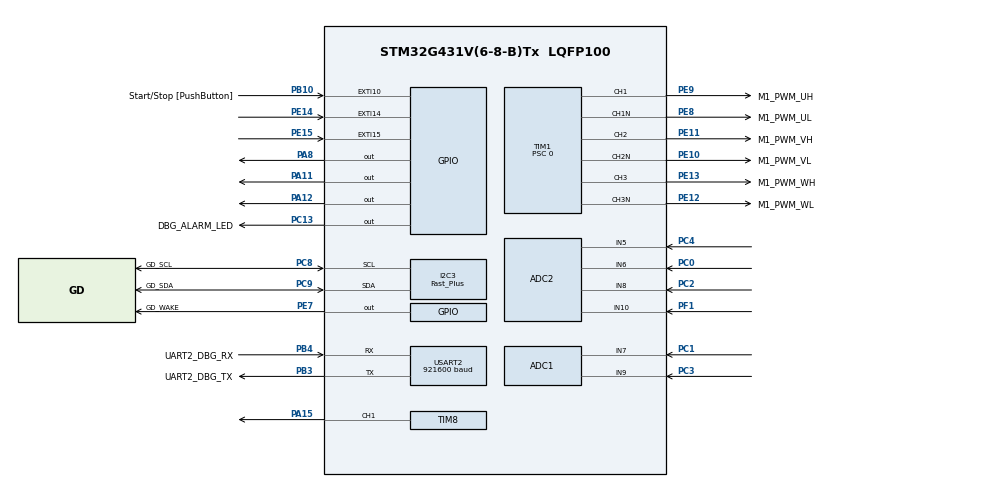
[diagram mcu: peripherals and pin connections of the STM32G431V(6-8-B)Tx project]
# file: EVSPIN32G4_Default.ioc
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ADC1.Channel-3\#ChannelRegularConversion=ADC_CHANNEL_7
ADC1.Channel-4\#ChannelRegularConversion=ADC_CHANNEL_9
ADC1.Channel-5\#ChannelRegularConversion=ADC_CHANNEL_9
ADC1.Channel-6\#ChannelRegularConversion=ADC_CHANNEL_7
ADC1.Channel-7\#ChannelRegularConversion=ADC_CHANNEL_7
ADC1.Channel-8\#ChannelRegularConversion=ADC_CHANNEL_7
ADC1.ClockPrescaler=ADC_CLOCK_ASYNC_DIV1
ADC1.DMAContinuousRequests=ENABLE
ADC1.DiscontinuousConvMode=ENABLE
ADC1.ExternalTrigConv=ADC_EXTERNALTRIG_T1_TRGO2
ADC1.ExternalTrigConvEdge=ADC_EXTERNALTRIGCONVEDGE_RISINGFALLING
ADC1.NbrOfConversion=6
ADC1.NbrOfConversionFlag=1
ADC1.OffsetNumber-3\#ChannelRegularConversion=ADC_OFFSET_NONE
ADC1.OffsetNumber-4\#ChannelRegularConversion=ADC_OFFSET_NONE
ADC1.OffsetNumber-5\#ChannelRegularConversion=ADC_OFFSET_NONE
ADC1.OffsetNumber-6\#ChannelRegularConversion=ADC_OFFSET_NONE
ADC1.OffsetNumber-7\#ChannelRegularConversion=ADC_OFFSET_NONE
ADC1.OffsetNumber-8\#ChannelRegularConversion=ADC_OFFSET_NONE
ADC1.Rank-3\#ChannelRegularConversion=1
ADC1.Rank-4\#ChannelRegularConversion=2
ADC1.Rank-5\#ChannelRegularConversion=3
ADC1.Rank-6\#ChannelRegularConversion=4
ADC1.Rank-7\#ChannelRegularConversion=5
ADC1.Rank-8\#ChannelRegularConversion=6
ADC1.SamplingTime-3\#ChannelRegularConversion=ADC_SAMPLETIME_6CYCLES_5
ADC1.SamplingTime-4\#ChannelRegularConversion=ADC_SAMPLETIME_6CYCLES_5
ADC1.SamplingTime-5\#ChannelRegularConversion=ADC_SAMPLETIME_6CYCLES_5
ADC1.SamplingTime-6\#ChannelRegularConversion=ADC_SAMPLETIME_6CYCLES_5
ADC1.SamplingTime-7\#ChannelRegularConversion=ADC_SAMPLETIME_6CYCLES_5
ADC1.SamplingTime-8\#ChannelRegularConversion=ADC_SAMPLETIME_6CYCLES_5
ADC1.master=1
ADC2.Channel-0\#ChannelRegularConversion=ADC_CHANNEL_5
ADC2.Channel-1\#ChannelRegularConversion=ADC_CHANNEL_8
ADC2.Channel-2\#ChannelRegularConversion=ADC_CHANNEL_10
ADC2.ClockPrescaler=ADC_CLOCK_ASYNC_DIV1
ADC2.DMAContinuousRequests=ENABLE
ADC2.DiscontinuousConvMode=ENABLE
ADC2.EOCSelection=ADC_EOC_SINGLE_CONV
ADC2.EnableInjectedConversion=ENABLE
ADC2.ExternalTrigInjecConv=ADC_EXTERNALTRIGINJEC_T8_TRGO2
ADC2.ExternalTrigInjecConvEdge=ADC_EXTERNALTRIGINJECCONV_EDGE_RISING
ADC2.InjNumberOfConversion=1
ADC2.InjectedChannel-3\#ChannelInjectedConversion=ADC_CHANNEL_6
ADC2.InjectedOffsetNumber-3\#ChannelInjectedConversion=ADC_OFFSET_NONE
ADC2.InjectedRank-3\#ChannelInjectedConversion=1
ADC2.InjectedSamplingTime-3\#ChannelInjectedConversion=ADC_SAMPLETIME_6CYCLES_5
ADC2.NbrOfConversion=3
ADC2.NbrOfConversionFlag=1
ADC2.NbrOfDiscConversion=3
ADC2.OffsetNumber-0\#ChannelRegularConversion=ADC_OFFSET_NONE
ADC2.OffsetNumber-1\#ChannelRegularConversion=ADC_OFFSET_NONE
ADC2.OffsetNumber-2\#ChannelRegularConversion=ADC_OFFSET_NONE
ADC2.Rank-0\#ChannelRegularConversion=1
ADC2.Rank-1\#ChannelRegularConversion=2
ADC2.Rank-2\#ChannelRegularConversion=3
ADC2.Rank1_Channel=ADC_CHANNEL_6
ADC2.SamplingTime-0\#ChannelRegularConversion=ADC_SAMPLETIME_6CYCLES_5
ADC2.SamplingTime-1\#ChannelRegularConversion=ADC_SAMPLETIME_6CYCLES_5
ADC2.SamplingTime-2\#ChannelRegularConversion=ADC_SAMPLETIME_6CYCLES_5
ADC2.injectedQueueMode=DISABLE
Dma.ADC1.0.Direction=DMA_PERIPH_TO_MEMORY
Dma.ADC1.0.EventEnable=DISABLE
Dma.ADC1.0.Instance=DMA1_Channel1
Dma.ADC1.0.MemDataAlignment=DMA_MDATAALIGN_HALFWORD
Dma.ADC1.0.MemInc=DMA_MINC_ENABLE
Dma.ADC1.0.Mode=DMA_CIRCULAR
Dma.ADC1.0.PeriphDataAlignment=DMA_PDATAALIGN_HALFWORD
Dma.ADC1.0.PeriphInc=DMA_PINC_DISABLE
Dma.ADC1.0.Polarity=HAL_DMAMUX_REQ_GEN_RISING
Dma.ADC1.0.Priority=DMA_PRIORITY_VERY_HIGH
Dma.ADC1.0.RequestNumber=1
Dma.ADC1.0.SignalID=NONE
Dma.ADC1.0.SyncEnable=DISABLE
Dma.ADC1.0.SyncPolarity=HAL_DMAMUX_SYNC_NO_EVENT
Dma.ADC1.0.SyncRequestNumber=1
Dma.ADC1.0.SyncSignalID=NONE
Dma.ADC2.2.Direction=DMA_PERIPH_TO_MEMORY
Dma.ADC2.2.EventEnable=DISABLE
Dma.ADC2.2.Instance=DMA1_Channel2
Dma.ADC2.2.MemDataAlignment=DMA_MDATAALIGN_HALFWORD
Dma.ADC2.2.MemInc=DMA_MINC_ENABLE
Dma.ADC2.2.Mode=DMA_CIRCULAR
Dma.ADC2.2.PeriphDataAlignment=DMA_PDATAALIGN_HALFWORD
Dma.ADC2.2.PeriphInc=DMA_PINC_DISABLE
Dma.ADC2.2.Polarity=HAL_DMAMUX_REQ_GEN_RISING
Dma.ADC2.2.Priority=DMA_PRIORITY_MEDIUM
Dma.ADC2.2.RequestNumber=1
Dma.ADC2.2.SignalID=NONE
Dma.ADC2.2.SyncEnable=DISABLE
Dma.ADC2.2.SyncPolarity=HAL_DMAMUX_SYNC_NO_EVENT
Dma.ADC2.2.SyncRequestNumber=1
Dma.ADC2.2.SyncSignalID=NONE
Dma.Request0=ADC1
Dma.Request1=TIM1_CH4
Dma.Request2=ADC2
Dma.TIM1_CH4.1.Direction=DMA_MEMORY_TO_PERIPH
Dma.TIM1_CH4.1.EventEnable=DISABLE
Dma.TIM1_CH4.1.Instance=DMA1_Channel4
Dma.TIM1_CH4.1.MemDataAlignment=DMA_MDATAALIGN_HALFWORD
Dma.TIM1_CH4.1.MemInc=DMA_MINC_ENABLE
Dma.TIM1_CH4.1.Mode=DMA_CIRCULAR
Dma.TIM1_CH4.1.PeriphDataAlignment=DMA_PDATAALIGN_HALFWORD
Dma.TIM1_CH4.1.PeriphInc=DMA_PINC_DISABLE
Dma.TIM1_CH4.1.Polarity=HAL_DMAMUX_REQ_GEN_RISING
Dma.TIM1_CH4.1.Priority=DMA_PRIORITY_VERY_HIGH
Dma.TIM1_CH4.1.RequestNumber=1
Dma.TIM1_CH4.1.SignalID=NONE
Dma.TIM1_CH4.1.SyncEnable=DISABLE
Dma.TIM1_CH4.1.SyncPolarity=HAL_DMAMUX_SYNC_NO_EVENT
Dma.TIM1_CH4.1.SyncRequestNumber=1
Dma.TIM1_CH4.1.SyncSignalID=NONE
I2C3.I2C_Speed_Mode=I2C_Fast_Plus
I2C3.Timing=0x00000107
Mcu.Family=STM32G4
Mcu.Name=STM32G431V(6-8-B)Tx
Mcu.Package=LQFP100
NVIC.ADC1_2_IRQn=true\:2\:0\:true\:false\:true\:true\:true\:true
NVIC.DMA1_Channel1_IRQn=true\:0\:0\:false\:false\:true\:true\:true\:true
NVIC.DMA1_Channel2_IRQn=true\:0\:0\:false\:false\:true\:true\:true\:true
NVIC.DMA1_Channel4_IRQn=true\:0\:0\:false\:false\:true\:true\:true\:true
NVIC.EXTI15_10_IRQn=true\:6\:0\:true\:false\:true\:true\:true\:true
NVIC.PriorityGroup=NVIC_PRIORITYGROUP_3
NVIC.TIM1_UP_TIM16_IRQn=true\:1\:0\:true\:false\:true\:true\:true\:true
NVIC.TIM8_CC_IRQn=true\:0\:0\:false\:false\:true\:true\:true\:true
NVIC.TIM8_UP_IRQn=true\:0\:0\:false\:false\:true\:true\:true\:true
NVIC.USART2_IRQn=true\:7\:0\:true\:false\:true\:true\:true\:true
PA11.Signal=GPIO_Output
PA12.Signal=GPIO_Output
PA13.GPIO_Label=TMS
PA13.Mode=Serial_Wire
PA13.Signal=SYS_JTMS-SWDIO
PA14.GPIO_Label=TCK
PA14.Mode=Serial_Wire
PA14.Signal=SYS_JTCK-SWCLK
PA15.Signal=S_TIM8_CH1
PA8.Signal=GPIO_Output
PB10.GPIO_Label=Start/Stop [PushButton]
PB10.GPIO_ModeDefaultEXTI=GPIO_MODE_IT_RISING
PB10.GPIO_PuPd=GPIO_NOPULL
PB10.Signal=GPXTI10
PB3.GPIO_Label=UART2_DBG_TX
PB3.Mode=Asynchronous
PB3.Signal=USART2_TX
PB4.GPIO_Label=UART2_DBG_RX
PB4.Mode=Asynchronous
PB4.Signal=USART2_RX
PC0.Mode=IN6-Single-Ended
PC0.Signal=ADC2_IN6
PC1.Mode=IN7-Single-Ended
PC1.Signal=ADC1_IN7
PC13.GPIO_Label=DBG_ALARM_LED
PC13.Signal=GPIO_Output
PC2.Mode=IN8-Single-Ended
PC2.Signal=ADC2_IN8
PC3.Mode=IN9-Single-Ended
PC3.Signal=ADC1_IN9
PC4.Mode=IN5-Single-Ended
PC4.Signal=ADC2_IN5
PC8.GPIO_Label=GD_SCL
PC8.Mode=I2C
PC8.Signal=I2C3_SCL
PC9.GPIO_Label=GD_SDA
PC9.Mode=I2C
PC9.Signal=I2C3_SDA
PE10.GPIO_Label=M1_PWM_VL
PE10.GPIO_PuPd=GPIO_PULLDOWN
PE10.GPIO_Speed=GPIO_SPEED_FREQ_HIGH
PE10.Mode=PWM Generation2 CH2 CH2N
PE10.Signal=TIM1_CH2N
PE11.GPIO_Label=M1_PWM_VH
PE11.GPIO_PuPd=GPIO_PULLDOWN
PE11.GPIO_Speed=GPIO_SPEED_FREQ_HIGH
PE11.Signal=S_TIM1_CH2
PE12.GPIO_Label=M1_PWM_WL
PE12.GPIO_PuPd=GPIO_PULLDOWN
PE12.GPIO_Speed=GPIO_SPEED_FREQ_HIGH
PE12.Mode=PWM Generation3 CH3 CH3N
PE12.Signal=TIM1_CH3N
PE13.GPIO_Label=M1_PWM_WH
PE13.GPIO_PuPd=GPIO_PULLDOWN
PE13.GPIO_Speed=GPIO_SPEED_FREQ_HIGH
PE13.Signal=S_TIM1_CH3
PE14.GPIO_ModeDefaultEXTI=GPIO_MODE_IT_RISING_FALLING
PE14.GPIO_PuPd=GPIO_PULLUP
PE14.Signal=GPXTI14
PE15.GPIO_ModeDefaultEXTI=GPIO_MODE_IT_FALLING
PE15.GPIO_PuPd=GPIO_PULLUP
PE15.Signal=GPXTI15
PE7.GPIO_Label=GD_WAKE
PE7.PinState=GPIO_PIN_SET
PE7.Signal=GPIO_Output
PE8.GPIO_Label=M1_PWM_UL
PE8.GPIO_PuPd=GPIO_PULLDOWN
PE8.GPIO_Speed=GPIO_SPEED_FREQ_HIGH
PE8.Mode=PWM Generation1 CH1 CH1N
PE8.Signal=TIM1_CH1N
PE9.GPIO_Label=M1_PWM_UH
PE9.GPIO_PuPd=GPIO_PULLDOWN
PE9.GPIO_Speed=GPIO_SPEED_FREQ_HIGH
PE9.Signal=S_TIM1_CH1
PF1-OSC_OUT.Mode=IN10-Single-Ended
PF1-OSC_OUT.Signal=ADC2_IN10
ProjectManager.HeapSize=0x200
ProjectManager.StackSize=0x400
ProjectManager.TargetToolchain=EWARM V8.32
RCC.ADC12CLockSelection=RCC_ADC12CLKSOURCE_PLL
RCC.ADC12Freq_Value=42500000
RCC.AHBFreq_Value=170000000
RCC.APB1Freq_Value=170000000
RCC.APB1TimFreq_Value=170000000
RCC.APB2Freq_Value=170000000
RCC.APB2TimFreq_Value=170000000
RCC.CortexFreq_Value=170000000
RCC.EXTERNAL_CLOCK_VALUE=12288000
RCC.HCLKFreq_Value=170000000
RCC.HSE_VALUE=24000000
RCC.HSI48_VALUE=48000000
RCC.HSI_VALUE=16000000
RCC.I2C3CLockSelection=RCC_I2C3CLKSOURCE_HSI
RCC.LSE_VALUE=32768
RCC.PLLM=RCC_PLLM_DIV4
RCC.PLLN=85
RCC.PLLP=RCC_PLLP_DIV8
RCC.SYSCLKFreq_VALUE=170000000
RCC.SYSCLKSource=RCC_SYSCLKSOURCE_PLLCLK
RCC.USART2CLockSelection=RCC_USART2CLKSOURCE_HSI
RCC.USBFreq_Value=170000000
RCC.VCOOutputFreq_Value=340000000
SH.S_TIM1_CH1.0=TIM1_CH1,PWM Generation1 CH1 CH1N
SH.S_TIM1_CH2.0=TIM1_CH2,PWM Generation2 CH2 CH2N
SH.S_TIM1_CH3.0=TIM1_CH3,PWM Generation3 CH3 CH3N
SH.S_TIM8_CH1.0=TIM8_CH1,PWM Generation1 CH1
TIM1.AutoReloadPreload=TIM_AUTORELOAD_PRELOAD_DISABLE
TIM1.AutomaticOutput=TIM_AUTOMATICOUTPUT_DISABLE
TIM1.Break2Filter=0
TIM1.Break2Polarity=TIM_BREAK2POLARITY_HIGH
TIM1.Break2State=TIM_BREAK2_DISABLE
TIM1.BreakFilter=0
TIM1.BreakPolarity=TIM_BREAKPOLARITY_HIGH
TIM1.BreakState=TIM_BREAK_DISABLE
TIM1.Channel-Output\ Compare4\ No\ Output=TIM_CHANNEL_4
TIM1.Channel-PWM\ Generation1\ CH1\ CH1N=TIM_CHANNEL_1
TIM1.Channel-PWM\ Generation2\ CH2\ CH2N=TIM_CHANNEL_2
TIM1.Channel-PWM\ Generation3\ CH3\ CH3N=TIM_CHANNEL_3
TIM1.ClearInputSource=TIM_CLEARINPUTSOURCE_NONE
TIM1.ClockDivision=TIM_CLOCKDIVISION_DIV1
TIM1.CounterMode=TIM_COUNTERMODE_CENTERALIGNED3
TIM1.DeadTime=0
TIM1.LockLevel=TIM_LOCKLEVEL_OFF
TIM1.OCIdleState_1=TIM_OCIDLESTATE_RESET
TIM1.OCIdleState_2=TIM_OCIDLESTATE_RESET
TIM1.OCIdleState_3=TIM_OCIDLESTATE_RESET
TIM1.OCIdleState_4=TIM_OCIDLESTATE_RESET
TIM1.OCMode_4=TIM_OCMODE_TOGGLE
TIM1.OCMode_PWM-PWM\ Generation1\ CH1\ CH1N=TIM_OCMODE_PWM1
TIM1.OCMode_PWM-PWM\ Generation2\ CH2\ CH2N=TIM_OCMODE_PWM1
TIM1.OCMode_PWM-PWM\ Generation3\ CH3\ CH3N=TIM_OCMODE_PWM1
TIM1.OCNIdleState_1=TIM_OCNIDLESTATE_RESET
TIM1.OCNIdleState_2=TIM_OCNIDLESTATE_RESET
TIM1.OCNIdleState_3=TIM_OCNIDLESTATE_RESET
TIM1.OCNPolarity_1=TIM_OCNPOLARITY_HIGH
TIM1.OCNPolarity_2=TIM_OCNPOLARITY_HIGH
TIM1.OCNPolarity_3=TIM_OCNPOLARITY_HIGH
TIM1.OCPolarity_1=TIM_OCPOLARITY_HIGH
TIM1.OCPolarity_2=TIM_OCPOLARITY_HIGH
TIM1.OCPolarity_3=TIM_OCPOLARITY_HIGH
TIM1.OCPolarity_4=TIM_OCPOLARITY_HIGH
TIM1.OffStateIDLEMode=TIM_OSSI_DISABLE
TIM1.OffStateRunMode=TIM_OSSR_DISABLE
TIM1.PeriodNoDither=((PWM_PERIOD_CYCLES) / 2)
TIM1.Prescaler=0
TIM1.PulseNoDither_1=300
TIM1.PulseNoDither_2=600
TIM1.PulseNoDither_3=900
TIM1.RepetitionCounter=0
TIM1.SourceBRK2COMP1=TIM_BREAKINPUTSOURCE_DISABLE
TIM1.SourceBRK2COMP2=TIM_BREAKINPUTSOURCE_DISABLE
TIM1.SourceBRK2COMP4=TIM_BREAKINPUTSOURCE_DISABLE
TIM1.SourceBRK2DigInput=TIM_BREAKINPUTSOURCE_DISABLE
TIM1.TIM_MasterOutputTrigger=TIM_TRGO_RESET
TIM1.TIM_MasterOutputTrigger2=TIM_TRGO2_OC4REF_RISINGFALLING
TIM1.TIM_MasterSlaveMode=TIM_MASTERSLAVEMODE_DISABLE
TIM8.Channel-PWM\ Generation1\ CH1=TIM_CHANNEL_1
TIM8.Channel-PWM\ Generation4\ No\ Output=TIM_CHANNEL_4
TIM8.OCMode_PWM-PWM\ Generation4\ No\ Output=TIM_OCMODE_PWM2
TIM8.PeriodNoDither=8000
TIM8.PulseNoDither_1=4000
TIM8.PulseNoDither_4=2000
TIM8.TIM_MasterOutputTrigger2=TIM_TRGO2_OC4REF
USART2.BaudRate=921600
USART2.VirtualMode-Asynchronous=VM_ASYNC
VP_CORDIC_VS_CORDIC.Mode=CORDIC_Activate
VP_SYS_VS_DBSignals.Mode=DisableDeadBatterySignals
VP_TIM1_VS_ClockSourceINT.Mode=Internal
VP_TIM1_VS_no_output4.Mode=Output Compare4 No Output
VP_TIM8_VS_ClockSourceINT.Mode=Internal
VP_TIM8_VS_no_output4.Mode=PWM Generation4 No Output
board=custom

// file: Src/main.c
/* USER CODE BEGIN Header */
/**
******************************************************************************
* @file           : main.c
* @brief          : Main program body
******************************************************************************
* @attention
*
* <h2><center>&copy; Copyright (c) 2022 STMicroelectronics.
* All rights reserved.</center></h2>
*
* This software component is licensed by ST under BSD 3-Clause license,
* the "License"; You may not use this file except in compliance with the
* License. You may obtain a copy of the License at:
*                        opensource.org/licenses/BSD-3-Clause
*
******************************************************************************
*/
/* USER CODE END Header */
#include "main.h"

void SystemClock_Config(void);
static void MX_GPIO_Init(void);
static void MX_DMA_Init(void);
static void MX_ADC1_Init(void);
static void MX_CORDIC_Init(void);
static void MX_I2C3_Init(void);
static void MX_TIM1_Init(void);
static void MX_USART2_UART_Init(void);
static void MX_ADC2_Init(void);
static void MX_TIM8_Init(void);

/* USER CODE BEGIN 0 */
IWDG_UserTypeDef sIWDG;
WWDG_UserTypeDef sWWDG;
uint16_t uSoftwareResetFlag;

void WDG_Enable(void);
void STSPIN32G4_STBY_Recovery_for_CLK(void);

/* USER CODE END 0 */

int main(void)
{
  /* USER CODE BEGIN 1 */

	bSystemInitializeFinishFlag = NO;

	/** USER_CODE_01: Enable the HSE Clock Security System **/
//#define HSE_CSS_ENABLE
#ifdef HSE_CSS_ENABLE
  LL_RCC_HSE_EnableCSS();
	// If CSSF bit in RCC_CIFR register has been Set by hardware.
	// (when a failure is detected in the HSE oscillator.)
	if(LL_RCC_IsActiveFlag_HSECSS())
	{
		// Cleared by software setting the CSSC bit.
		LL_RCC_ClearFlag_HSECSS();
	}
#endif

  /* USER CODE END 1 */

  /* MCU Configuration--------------------------------------------------------*/

  /* Reset of all peripherals, Initializes the Flash interface and the Systick. */
  LL_APB2_GRP1_EnableClock(LL_APB2_GRP1_PERIPH_SYSCFG);
  LL_APB1_GRP1_EnableClock(LL_APB1_GRP1_PERIPH_PWR);

  /* System interrupt init*/
  NVIC_SetPriorityGrouping(NVIC_PRIORITYGROUP_3);

  /* SysTick_IRQn interrupt configuration */
  NVIC_SetPriority(SysTick_IRQn, NVIC_EncodePriority(NVIC_GetPriorityGrouping(),4, 0));

  /** Disable the internal Pull-Up in Dead Battery pins of UCPD peripheral
  */
  LL_PWR_DisableUCPDDeadBattery();

  /* USER CODE BEGIN Init */

	/** USER_CODE_03: Freeze Peripheral's clock when debugging **/
  LL_DBGMCU_APB2_GRP1_FreezePeriph(LL_DBGMCU_APB2_GRP1_TIM1_STOP);
  LL_DBGMCU_APB1_GRP1_FreezePeriph(LL_DBGMCU_APB1_GRP1_TIM2_STOP);
  LL_DBGMCU_APB1_GRP1_FreezePeriph(LL_DBGMCU_APB1_GRP1_TIM3_STOP);
  LL_DBGMCU_APB1_GRP1_FreezePeriph(LL_DBGMCU_APB1_GRP1_TIM7_STOP);
	LL_DBGMCU_APB1_GRP1_FreezePeriph(LL_DBGMCU_APB1_GRP1_WWDG_STOP);
	LL_DBGMCU_APB1_GRP1_FreezePeriph(LL_DBGMCU_APB1_GRP1_IWDG_STOP);

	/** USER_CODE_04: Gate Driver Initialization before system clock configurations **/
  MX_GPIO_Init();
  MX_I2C3_Init();
  Init_STSPING4_GateDriver_Register();

  /* USER CODE END Init */

  /* Configure the system clock */
  SystemClock_Config();

  /* USER CODE BEGIN SysInit */
	/** USER_CODE_02: Systick interrupt enable **/
  SysTick->CTRL |= SysTick_CTRL_TICKINT_Msk;

	/** USER_CODE_05: Check IWDG reset and Software reset**/
  /* Check IWDG reset */
	sIWDG.ResetFlag = CLR;
  if (LL_RCC_IsActiveFlag_IWDGRST()){
		User_printf(SCI_DEBUG, "\r\n[!] Reboot from IWDG reset !! ");
		sIWDG.ResetFlag = SET;
  }
  /* Check WWDG reset */
	sWWDG.ResetFlag = CLR;
  if (LL_RCC_IsActiveFlag_WWDGRST()){
		User_printf(SCI_DEBUG, "\r\n[!] Reboot from WWDG reset !! ");
		sWWDG.ResetFlag = SET;
  }
  /* Check software reset */
	uSoftwareResetFlag = CLR;
  if (LL_RCC_IsActiveFlag_SFTRST()){
		User_printf(SCI_DEBUG, "\r\n[!] Reboot from software reset !! ");
		uSoftwareResetFlag = SET;
  }
  LL_RCC_ClearResetFlags(); // clear reset flag in WD
	LL_mDelay(2000);

  /* USER CODE END SysInit */

  /* Initialize all configured peripherals */
  MX_GPIO_Init();
  MX_DMA_Init();
  MX_ADC1_Init();
  MX_CORDIC_Init();
  MX_I2C3_Init();
  MX_TIM1_Init();
  MX_USART2_UART_Init();
  MX_ADC2_Init();
  MX_TIM8_Init();
  /* USER CODE BEGIN 2 */

	/** USER_CODE_06: User Peripheral initializations**/
  // ==== 1. Initialize Debug print Flags
  Init_DebugFlag(); // enable/disable debug message you want
  Init_User_UART(); // intialize uart

  // ==== 2. Print system version & help message
	for(int _for_i = 0; _for_i<4; _for_i++)			EMPTY_LINE(SCI_DEBUG);
  if (sIWDG.ResetFlag == SET)		User_printf(SCI_DEBUG, "\r\n[!] Booting from IWDG reset !! ");
	if (sWWDG.ResetFlag == SET)		User_printf(SCI_DEBUG, "\r\n[!] Booting from WWDG reset !! ");
	if (uSoftwareResetFlag == SET)User_printf(SCI_DEBUG, "\r\n[!] Booting from Software reset !! ");
  DebugWelcomeMessage();

  // ==== 3. Initialize System Variables
	User_printf(SCI_DEBUG, "\r\n Initialize System Variables....  ");
  stSpinSysCtrl.PRIMARY_SEQ.all = 0x0000;
  Clear_All_STSPIN32G_REG_Values();

  // ==== 4. Initialize other Peripherals
  // -------4.1. STSPIN32G4 Gate Driver default configuration
	User_printf(SCI_DEBUG, "\r\n Initialize STSPIN32G4 Gate Driver default configuration.... ");
  //Init_STSPING4_GateDriver_Register();

  // -------4.2. ADC Calibration
	User_printf(SCI_DEBUG, "\r\n Initialize STSPIN32G4 ADC Calibration.... ");
	LL_ADC_StartCalibration(ADC1, LL_ADC_SINGLE_ENDED);
	while (LL_ADC_IsCalibrationOnGoing(ADC1) != 0){}	// Wait until ADCAL=0

	LL_ADC_StartCalibration(ADC2, LL_ADC_SINGLE_ENDED);
	while (LL_ADC_IsCalibrationOnGoing(ADC2) != 0){}	// Wait until ADCAL=0

	// -------4.3. External interrupt Enable
	User_printf(SCI_DEBUG, "\r\n Initialize External interrupt Enable.... ");
	// GD_READY_Pin
	LL_EXTI_EnableRisingTrig_0_31(LL_EXTI_LINE_14);
	LL_EXTI_EnableFallingTrig_0_31(LL_EXTI_LINE_14);
	LL_EXTI_EnableIT_0_31(LL_EXTI_LINE_14);
	// GD_NFAULT_Pin
	//LL_EXTI_EnableRisingTrig_0_31(LL_EXTI_LINE_15);
	LL_EXTI_EnableFallingTrig_0_31(LL_EXTI_LINE_15);
	LL_EXTI_EnableIT_0_31(LL_EXTI_LINE_15);

  // ==== 5. Enter Main Sequence
  //run test mode start, communication protocol initialize and etc..
	User_printf(SCI_DEBUG, "\r\n ADC, PWM, DMA run test start,.... ");
	ADC2_Init();
	MotorStart();

	/** USER_CODE_07: Enable Watchdog before entering main loop**/
	WDG_Enable();

  /* USER CODE END 2 */

  /* Infinite loop */
  /* USER CODE BEGIN WHILE */

	User_printf(SCI_DEBUG, "\r\n Entering Main while loop.... \r\n \r\n ");
	MACHINE_NAME(SCI_DEBUG);
	bSystemInitializeFinishFlag = YES;
  while (1)
  {
    // MainLoop-00. Watchdog reload
#ifdef WATCHDOG_ENABLE
    if(sIWDG.Enable == ENABLE){
      LL_IWDG_ReloadCounter(IWDG); //WRITE_REG(IWDG->KR, LL_IWDG_KEY_RELOAD);
    }
    if(sWWDG.Enable == ENABLE){
			LL_WWDG_SetCounter(WWDG, sWWDG.Reload); //MODIFY_REG(WWDG->CR, WWDG_CR_T, sWWDG.Reload);
    }
#endif

    // MainLoop-01. Check communications
    if(stSci_Debug.bRX_flag)
    {
      stSci_Debug.bRX_flag = FALSE;
      DebugCmdParser(&stSci_Debug);
    }

    // MainLoop-02. Periodic functions
    PeriodicFunction();

    // MainLoop-03. Main Loop Start
    //PrimarySequence();

		// MainLoop-04. fault check
		// 04-1. bReadyPinExternalInterruptFlag
		if(bReadyPinExternalInterruptFlag == YES)
		{
			bReadyPinExternalInterruptFlag = NO;
			if(bReadyPinInput == HIGH)
			{
				//User_printf(SCI_DEBUG, "\r\n[!] RDY Rising ");
			}

			if(bReadyPinInput == LOW)
			{
				//User_printf(SCI_DEBUG, "\r\n[!] RDY Falling ");
			}
			MACHINE_NAME(SCI_DEBUG);
		}

		// 04-2. bFaultPinExternalInterruptFlag
		if(bFaultPinExternalInterruptFlag == YES)
		{
			bFaultPinExternalInterruptFlag = NO;
			bFaultPinInput = HIGH;

			STSPIN32GX_getStatus();
			if(stDbgPrt.bDebug) User_printf(SCI_DEBUG, "\r\n ****** nFault Error ***** ");
			if(stDbgPrt.bDebug) User_printf(SCI_DEBUG, "\r\n [0x80] Reports the device status: %x", 		stSpinReg.STATUS.cValue.all);
			if(stDbgPrt.bDebug) User_printf(SCI_DEBUG, "\r\n    - LOCK      = %d (0: Unlocked, 1:Locked)", 		stSpinReg.STATUS.cValue.bit.ubLOCK);
			if(stDbgPrt.bDebug) User_printf(SCI_DEBUG, "\r\n    - RESET     = %d (0: No reset, 1: Reset)", 		stSpinReg.STATUS.cValue.bit.ubRESET);
			if(stDbgPrt.bDebug) User_printf(SCI_DEBUG, "\r\n    - VDS_P     = %d (0: Not triggered, 1: Triggered)", 	stSpinReg.STATUS.cValue.bit.ubVDS_P);
			if(stDbgPrt.bDebug) User_printf(SCI_DEBUG, "\r\n    - THSD      = %d (0: Not triggered, 1: Triggered)", 	stSpinReg.STATUS.cValue.bit.ubTHSD);
  		if(stDbgPrt.bDebug) User_printf(SCI_DEBUG, "\r\n    - VCC_UVLO  = %d (0: Above Threshold, 1: Under Threshold)",stSpinReg.STATUS.cValue.bit.ubVCC_UVLO);
			MACHINE_NAME(SCI_DEBUG);
		}

    /* USER CODE END WHILE */

  }
}

void SystemClock_Config(void)
{
  LL_FLASH_SetLatency(LL_FLASH_LATENCY_4);
  while(LL_FLASH_GetLatency() != LL_FLASH_LATENCY_4)
  {
  }
  LL_PWR_EnableRange1BoostMode();
  LL_RCC_HSI_Enable();
   /* Wait till HSI is ready */
  while(LL_RCC_HSI_IsReady() != 1)
  {
  }

  LL_RCC_HSI_SetCalibTrimming(64);
  LL_RCC_PLL_ConfigDomain_SYS(LL_RCC_PLLSOURCE_HSI, LL_RCC_PLLM_DIV_4, 85, LL_RCC_PLLR_DIV_2);
  LL_RCC_PLL_ConfigDomain_ADC(LL_RCC_PLLSOURCE_HSI, LL_RCC_PLLM_DIV_4, 85, LL_RCC_PLLP_DIV_8);
  LL_RCC_PLL_EnableDomain_SYS();
  LL_RCC_PLL_EnableDomain_ADC();
  LL_RCC_PLL_Enable();
   /* Wait till PLL is ready */
  while(LL_RCC_PLL_IsReady() != 1)
  {
  }

  LL_RCC_SetSysClkSource(LL_RCC_SYS_CLKSOURCE_PLL);
  LL_RCC_SetAHBPrescaler(LL_RCC_SYSCLK_DIV_2);
   /* Wait till System clock is ready */
  while(LL_RCC_GetSysClkSource() != LL_RCC_SYS_CLKSOURCE_STATUS_PLL)
  {
  }

  /* Insure 1µs transition state at intermediate medium speed clock based on DWT */
  CoreDebug->DEMCR |= CoreDebug_DEMCR_TRCENA_Msk;
  DWT->CTRL |= DWT_CTRL_CYCCNTENA_Msk;
  DWT->CYCCNT = 0;
  while(DWT->CYCCNT < 100);
  /* Set AHB prescaler*/
  LL_RCC_SetAHBPrescaler(LL_RCC_SYSCLK_DIV_1);
  LL_RCC_SetAPB1Prescaler(LL_RCC_APB1_DIV_1);
  LL_RCC_SetAPB2Prescaler(LL_RCC_APB2_DIV_1);

  LL_Init1msTick(170000000);

  LL_SetSystemCoreClock(170000000);
}

static void MX_ADC1_Init(void)
{

  LL_ADC_InitTypeDef ADC_InitStruct = {0};
  LL_ADC_REG_InitTypeDef ADC_REG_InitStruct = {0};
  LL_ADC_CommonInitTypeDef ADC_CommonInitStruct = {0};
  LL_ADC_INJ_InitTypeDef ADC_INJ_InitStruct = {0};

  LL_GPIO_InitTypeDef GPIO_InitStruct = {0};

  LL_RCC_SetADCClockSource(LL_RCC_ADC12_CLKSOURCE_PLL);

  /* Peripheral clock enable */
  LL_AHB2_GRP1_EnableClock(LL_AHB2_GRP1_PERIPH_ADC12);

  LL_AHB2_GRP1_EnableClock(LL_AHB2_GRP1_PERIPH_GPIOC);
  /**ADC1 GPIO Configuration
  PC1   ------> ADC1_IN7
  PC3   ------> ADC1_IN9
  */
  GPIO_InitStruct.Pin = LL_GPIO_PIN_1;
  GPIO_InitStruct.Mode = LL_GPIO_MODE_ANALOG;
  GPIO_InitStruct.Pull = LL_GPIO_PULL_NO;
  LL_GPIO_Init(GPIOC, &GPIO_InitStruct);

  GPIO_InitStruct.Pin = LL_GPIO_PIN_3;
  GPIO_InitStruct.Mode = LL_GPIO_MODE_ANALOG;
  GPIO_InitStruct.Pull = LL_GPIO_PULL_NO;
  LL_GPIO_Init(GPIOC, &GPIO_InitStruct);

  /* ADC1 DMA Init */

  /* ADC1 Init */
  LL_DMA_SetPeriphRequest(DMA1, LL_DMA_CHANNEL_1, LL_DMAMUX_REQ_ADC1);

  LL_DMA_SetDataTransferDirection(DMA1, LL_DMA_CHANNEL_1, LL_DMA_DIRECTION_PERIPH_TO_MEMORY);

  LL_DMA_SetChannelPriorityLevel(DMA1, LL_DMA_CHANNEL_1, LL_DMA_PRIORITY_VERYHIGH);

  LL_DMA_SetMode(DMA1, LL_DMA_CHANNEL_1, LL_DMA_MODE_CIRCULAR);

  LL_DMA_SetPeriphIncMode(DMA1, LL_DMA_CHANNEL_1, LL_DMA_PERIPH_NOINCREMENT);

  LL_DMA_SetMemoryIncMode(DMA1, LL_DMA_CHANNEL_1, LL_DMA_MEMORY_INCREMENT);

  LL_DMA_SetPeriphSize(DMA1, LL_DMA_CHANNEL_1, LL_DMA_PDATAALIGN_HALFWORD);

  LL_DMA_SetMemorySize(DMA1, LL_DMA_CHANNEL_1, LL_DMA_MDATAALIGN_HALFWORD);

  /* ADC1 interrupt Init */
  NVIC_SetPriority(ADC1_2_IRQn, NVIC_EncodePriority(NVIC_GetPriorityGrouping(),2, 0));
  NVIC_EnableIRQ(ADC1_2_IRQn);

  /** Common config
  */
  ADC_InitStruct.Resolution = LL_ADC_RESOLUTION_12B;
  ADC_InitStruct.DataAlignment = LL_ADC_DATA_ALIGN_RIGHT;
  ADC_InitStruct.LowPowerMode = LL_ADC_LP_MODE_NONE;
  LL_ADC_Init(ADC1, &ADC_InitStruct);
  ADC_REG_InitStruct.TriggerSource = LL_ADC_REG_TRIG_EXT_TIM1_TRGO2;
  ADC_REG_InitStruct.SequencerLength = LL_ADC_REG_SEQ_SCAN_ENABLE_6RANKS;
  ADC_REG_InitStruct.SequencerDiscont = LL_ADC_REG_SEQ_DISCONT_1RANK;
  ADC_REG_InitStruct.ContinuousMode = LL_ADC_REG_CONV_SINGLE;
  ADC_REG_InitStruct.DMATransfer = LL_ADC_REG_DMA_TRANSFER_UNLIMITED;
  ADC_REG_InitStruct.Overrun = LL_ADC_REG_OVR_DATA_PRESERVED;
  LL_ADC_REG_Init(ADC1, &ADC_REG_InitStruct);
  LL_ADC_SetGainCompensation(ADC1, 0);
  LL_ADC_SetOverSamplingScope(ADC1, LL_ADC_OVS_DISABLE);
  ADC_CommonInitStruct.CommonClock = LL_ADC_CLOCK_ASYNC_DIV1;
  ADC_CommonInitStruct.Multimode = LL_ADC_MULTI_INDEPENDENT;
  LL_ADC_CommonInit(__LL_ADC_COMMON_INSTANCE(ADC1), &ADC_CommonInitStruct);
  ADC_INJ_InitStruct.SequencerDiscont = LL_ADC_INJ_SEQ_DISCONT_DISABLE;
  ADC_INJ_InitStruct.TrigAuto = LL_ADC_INJ_TRIG_INDEPENDENT;
  LL_ADC_INJ_Init(ADC1, &ADC_INJ_InitStruct);
  LL_ADC_REG_SetTriggerEdge(ADC1, LL_ADC_REG_TRIG_EXT_RISINGFALLING);

  /* Disable ADC deep power down (enabled by default after reset state) */
  LL_ADC_DisableDeepPowerDown(ADC1);
  /* Enable ADC internal voltage regulator */
  LL_ADC_EnableInternalRegulator(ADC1);
  /* Delay for ADC internal voltage regulator stabilization. */
  /* Compute number of CPU cycles to wait for, from delay in us. */
  /* Note: Variable divided by 2 to compensate partially */
  /* CPU processing cycles (depends on compilation optimization). */
  /* Note: If system core clock frequency is below 200kHz, wait time */
  /* is only a few CPU processing cycles. */
  uint32_t wait_loop_index;
  wait_loop_index = ((LL_ADC_DELAY_INTERNAL_REGUL_STAB_US * (SystemCoreClock / (100000 * 2))) / 10);
  while(wait_loop_index != 0)
  {
    wait_loop_index--;
  }

  /** Configure Regular Channel
  */
  LL_ADC_REG_SetSequencerRanks(ADC1, LL_ADC_REG_RANK_1, LL_ADC_CHANNEL_7);
  LL_ADC_SetChannelSamplingTime(ADC1, LL_ADC_CHANNEL_7, LL_ADC_SAMPLINGTIME_6CYCLES_5);
  LL_ADC_SetChannelSingleDiff(ADC1, LL_ADC_CHANNEL_7, LL_ADC_SINGLE_ENDED);

  /** Configure Regular Channel
  */
  LL_ADC_REG_SetSequencerRanks(ADC1, LL_ADC_REG_RANK_2, LL_ADC_CHANNEL_9);
  LL_ADC_SetChannelSamplingTime(ADC1, LL_ADC_CHANNEL_9, LL_ADC_SAMPLINGTIME_6CYCLES_5);
  LL_ADC_SetChannelSingleDiff(ADC1, LL_ADC_CHANNEL_9, LL_ADC_SINGLE_ENDED);

  /** Configure Regular Channel
  */
  LL_ADC_REG_SetSequencerRanks(ADC1, LL_ADC_REG_RANK_3, LL_ADC_CHANNEL_9);
  LL_ADC_SetChannelSamplingTime(ADC1, LL_ADC_CHANNEL_9, LL_ADC_SAMPLINGTIME_6CYCLES_5);
  LL_ADC_SetChannelSingleDiff(ADC1, LL_ADC_CHANNEL_9, LL_ADC_SINGLE_ENDED);

  /** Configure Regular Channel
  */
  LL_ADC_REG_SetSequencerRanks(ADC1, LL_ADC_REG_RANK_4, LL_ADC_CHANNEL_7);
  LL_ADC_SetChannelSamplingTime(ADC1, LL_ADC_CHANNEL_7, LL_ADC_SAMPLINGTIME_6CYCLES_5);
  LL_ADC_SetChannelSingleDiff(ADC1, LL_ADC_CHANNEL_7, LL_ADC_SINGLE_ENDED);

  /** Configure Regular Channel
  */
  LL_ADC_REG_SetSequencerRanks(ADC1, LL_ADC_REG_RANK_5, LL_ADC_CHANNEL_7);
  LL_ADC_SetChannelSamplingTime(ADC1, LL_ADC_CHANNEL_7, LL_ADC_SAMPLINGTIME_6CYCLES_5);
  LL_ADC_SetChannelSingleDiff(ADC1, LL_ADC_CHANNEL_7, LL_ADC_SINGLE_ENDED);

  /** Configure Regular Channel
  */
  LL_ADC_REG_SetSequencerRanks(ADC1, LL_ADC_REG_RANK_6, LL_ADC_CHANNEL_7);
  LL_ADC_SetChannelSamplingTime(ADC1, LL_ADC_CHANNEL_7, LL_ADC_SAMPLINGTIME_6CYCLES_5);
  LL_ADC_SetChannelSingleDiff(ADC1, LL_ADC_CHANNEL_7, LL_ADC_SINGLE_ENDED);

}

static void MX_ADC2_Init(void)
{

  LL_ADC_InitTypeDef ADC_InitStruct = {0};
  LL_ADC_REG_InitTypeDef ADC_REG_InitStruct = {0};
  LL_ADC_INJ_InitTypeDef ADC_INJ_InitStruct = {0};

  LL_GPIO_InitTypeDef GPIO_InitStruct = {0};

  LL_RCC_SetADCClockSource(LL_RCC_ADC12_CLKSOURCE_PLL);

  /* Peripheral clock enable */
  LL_AHB2_GRP1_EnableClock(LL_AHB2_GRP1_PERIPH_ADC12);

  LL_AHB2_GRP1_EnableClock(LL_AHB2_GRP1_PERIPH_GPIOF);
  LL_AHB2_GRP1_EnableClock(LL_AHB2_GRP1_PERIPH_GPIOC);
  /**ADC2 GPIO Configuration
  PF1-OSC_OUT   ------> ADC2_IN10
  PC0   ------> ADC2_IN6
  PC2   ------> ADC2_IN8
  PC4   ------> ADC2_IN5
  */
  GPIO_InitStruct.Pin = LL_GPIO_PIN_1;
  GPIO_InitStruct.Mode = LL_GPIO_MODE_ANALOG;
  GPIO_InitStruct.Pull = LL_GPIO_PULL_NO;
  LL_GPIO_Init(GPIOF, &GPIO_InitStruct);

  GPIO_InitStruct.Pin = LL_GPIO_PIN_0;
  GPIO_InitStruct.Mode = LL_GPIO_MODE_ANALOG;
  GPIO_InitStruct.Pull = LL_GPIO_PULL_NO;
  LL_GPIO_Init(GPIOC, &GPIO_InitStruct);

  GPIO_InitStruct.Pin = LL_GPIO_PIN_2;
  GPIO_InitStruct.Mode = LL_GPIO_MODE_ANALOG;
  GPIO_InitStruct.Pull = LL_GPIO_PULL_NO;
  LL_GPIO_Init(GPIOC, &GPIO_InitStruct);

  GPIO_InitStruct.Pin = LL_GPIO_PIN_4;
  GPIO_InitStruct.Mode = LL_GPIO_MODE_ANALOG;
  GPIO_InitStruct.Pull = LL_GPIO_PULL_NO;
  LL_GPIO_Init(GPIOC, &GPIO_InitStruct);

  /* ADC2 DMA Init */

  /* ADC2 Init */
  LL_DMA_SetPeriphRequest(DMA1, LL_DMA_CHANNEL_2, LL_DMAMUX_REQ_ADC2);

  LL_DMA_SetDataTransferDirection(DMA1, LL_DMA_CHANNEL_2, LL_DMA_DIRECTION_PERIPH_TO_MEMORY);

  LL_DMA_SetChannelPriorityLevel(DMA1, LL_DMA_CHANNEL_2, LL_DMA_PRIORITY_MEDIUM);

  LL_DMA_SetMode(DMA1, LL_DMA_CHANNEL_2, LL_DMA_MODE_CIRCULAR);

  LL_DMA_SetPeriphIncMode(DMA1, LL_DMA_CHANNEL_2, LL_DMA_PERIPH_NOINCREMENT);

  LL_DMA_SetMemoryIncMode(DMA1, LL_DMA_CHANNEL_2, LL_DMA_MEMORY_INCREMENT);

  LL_DMA_SetPeriphSize(DMA1, LL_DMA_CHANNEL_2, LL_DMA_PDATAALIGN_HALFWORD);

  LL_DMA_SetMemorySize(DMA1, LL_DMA_CHANNEL_2, LL_DMA_MDATAALIGN_HALFWORD);

  /* ADC2 interrupt Init */
  NVIC_SetPriority(ADC1_2_IRQn, NVIC_EncodePriority(NVIC_GetPriorityGrouping(),2, 0));
  NVIC_EnableIRQ(ADC1_2_IRQn);

  /** Common config
  */
  ADC_InitStruct.Resolution = LL_ADC_RESOLUTION_12B;
  ADC_InitStruct.DataAlignment = LL_ADC_DATA_ALIGN_RIGHT;
  ADC_InitStruct.LowPowerMode = LL_ADC_LP_MODE_NONE;
  LL_ADC_Init(ADC2, &ADC_InitStruct);
  ADC_REG_InitStruct.TriggerSource = LL_ADC_REG_TRIG_SOFTWARE;
  ADC_REG_InitStruct.SequencerLength = LL_ADC_REG_SEQ_SCAN_ENABLE_3RANKS;
  ADC_REG_InitStruct.SequencerDiscont = LL_ADC_REG_SEQ_DISCONT_3RANKS;
  ADC_REG_InitStruct.ContinuousMode = LL_ADC_REG_CONV_SINGLE;
  ADC_REG_InitStruct.DMATransfer = LL_ADC_REG_DMA_TRANSFER_UNLIMITED;
  ADC_REG_InitStruct.Overrun = LL_ADC_REG_OVR_DATA_PRESERVED;
  LL_ADC_REG_Init(ADC2, &ADC_REG_InitStruct);
  LL_ADC_SetGainCompensation(ADC2, 0);
  LL_ADC_SetOverSamplingScope(ADC2, LL_ADC_OVS_DISABLE);
  ADC_INJ_InitStruct.TriggerSource = LL_ADC_INJ_TRIG_EXT_TIM8_TRGO2;
  ADC_INJ_InitStruct.SequencerLength = LL_ADC_INJ_SEQ_SCAN_DISABLE;
  ADC_INJ_InitStruct.SequencerDiscont = LL_ADC_INJ_SEQ_DISCONT_DISABLE;
  ADC_INJ_InitStruct.TrigAuto = LL_ADC_INJ_TRIG_INDEPENDENT;
  LL_ADC_INJ_Init(ADC2, &ADC_INJ_InitStruct);
  LL_ADC_INJ_SetQueueMode(ADC2, LL_ADC_INJ_QUEUE_DISABLE);
  LL_ADC_INJ_SetTriggerEdge(ADC2, LL_ADC_INJ_TRIG_EXT_RISING);

  /* Disable ADC deep power down (enabled by default after reset state) */
  LL_ADC_DisableDeepPowerDown(ADC2);
  /* Enable ADC internal voltage regulator */
  LL_ADC_EnableInternalRegulator(ADC2);
  /* Delay for ADC internal voltage regulator stabilization. */
  /* Compute number of CPU cycles to wait for, from delay in us. */
  /* Note: Variable divided by 2 to compensate partially */
  /* CPU processing cycles (depends on compilation optimization). */
  /* Note: If system core clock frequency is below 200kHz, wait time */
  /* is only a few CPU processing cycles. */
  uint32_t wait_loop_index;
  wait_loop_index = ((LL_ADC_DELAY_INTERNAL_REGUL_STAB_US * (SystemCoreClock / (100000 * 2))) / 10);
  while(wait_loop_index != 0)
  {
    wait_loop_index--;
  }

  /** Configure Regular Channel
  */
  LL_ADC_REG_SetSequencerRanks(ADC2, LL_ADC_REG_RANK_1, LL_ADC_CHANNEL_5);
  LL_ADC_SetChannelSamplingTime(ADC2, LL_ADC_CHANNEL_5, LL_ADC_SAMPLINGTIME_6CYCLES_5);
  LL_ADC_SetChannelSingleDiff(ADC2, LL_ADC_CHANNEL_5, LL_ADC_SINGLE_ENDED);

  /** Configure Regular Channel
  */
  LL_ADC_REG_SetSequencerRanks(ADC2, LL_ADC_REG_RANK_2, LL_ADC_CHANNEL_8);
  LL_ADC_SetChannelSamplingTime(ADC2, LL_ADC_CHANNEL_8, LL_ADC_SAMPLINGTIME_6CYCLES_5);
  LL_ADC_SetChannelSingleDiff(ADC2, LL_ADC_CHANNEL_8, LL_ADC_SINGLE_ENDED);

  /** Configure Regular Channel
  */
  LL_ADC_REG_SetSequencerRanks(ADC2, LL_ADC_REG_RANK_3, LL_ADC_CHANNEL_10);
  LL_ADC_SetChannelSamplingTime(ADC2, LL_ADC_CHANNEL_10, LL_ADC_SAMPLINGTIME_6CYCLES_5);
  LL_ADC_SetChannelSingleDiff(ADC2, LL_ADC_CHANNEL_10, LL_ADC_SINGLE_ENDED);

  /** Configure Injected Channel
  */
  LL_ADC_INJ_SetSequencerRanks(ADC2, LL_ADC_INJ_RANK_1, LL_ADC_CHANNEL_6);
  LL_ADC_SetChannelSamplingTime(ADC2, LL_ADC_CHANNEL_6, LL_ADC_SAMPLINGTIME_6CYCLES_5);
  LL_ADC_SetChannelSingleDiff(ADC2, LL_ADC_CHANNEL_6, LL_ADC_SINGLE_ENDED);

}

static void MX_CORDIC_Init(void)
{

  /* Peripheral clock enable */
  LL_AHB1_GRP1_EnableClock(LL_AHB1_GRP1_PERIPH_CORDIC);

  /* nothing else to be configured */

}

static void MX_I2C3_Init(void)
{

  LL_I2C_InitTypeDef I2C_InitStruct = {0};

  LL_GPIO_InitTypeDef GPIO_InitStruct = {0};

  LL_RCC_SetI2CClockSource(LL_RCC_I2C3_CLKSOURCE_HSI);

  LL_AHB2_GRP1_EnableClock(LL_AHB2_GRP1_PERIPH_GPIOC);
  /**I2C3 GPIO Configuration
  PC8   ------> I2C3_SCL
  PC9   ------> I2C3_SDA
  */
  GPIO_InitStruct.Pin = GD_SCL_Pin;
  GPIO_InitStruct.Mode = LL_GPIO_MODE_ALTERNATE;
  GPIO_InitStruct.Speed = LL_GPIO_SPEED_FREQ_LOW;
  GPIO_InitStruct.OutputType = LL_GPIO_OUTPUT_OPENDRAIN;
  GPIO_InitStruct.Pull = LL_GPIO_PULL_NO;
  GPIO_InitStruct.Alternate = LL_GPIO_AF_8;
  LL_GPIO_Init(GD_SCL_GPIO_Port, &GPIO_InitStruct);

  GPIO_InitStruct.Pin = GD_SDA_Pin;
  GPIO_InitStruct.Mode = LL_GPIO_MODE_ALTERNATE;
  GPIO_InitStruct.Speed = LL_GPIO_SPEED_FREQ_LOW;
  GPIO_InitStruct.OutputType = LL_GPIO_OUTPUT_OPENDRAIN;
  GPIO_InitStruct.Pull = LL_GPIO_PULL_NO;
  GPIO_InitStruct.Alternate = LL_GPIO_AF_8;
  LL_GPIO_Init(GD_SDA_GPIO_Port, &GPIO_InitStruct);

  /* Peripheral clock enable */
  LL_APB1_GRP1_EnableClock(LL_APB1_GRP1_PERIPH_I2C3);

  /** I2C Initialization
  */
  I2C_InitStruct.PeripheralMode = LL_I2C_MODE_I2C;
  I2C_InitStruct.Timing = 0x00000107;
  I2C_InitStruct.AnalogFilter = LL_I2C_ANALOGFILTER_ENABLE;
  I2C_InitStruct.DigitalFilter = 0;
  I2C_InitStruct.OwnAddress1 = 0;
  I2C_InitStruct.TypeAcknowledge = LL_I2C_ACK;
  I2C_InitStruct.OwnAddrSize = LL_I2C_OWNADDRESS1_7BIT;
  LL_I2C_Init(I2C3, &I2C_InitStruct);
  LL_I2C_EnableAutoEndMode(I2C3);
  LL_I2C_SetOwnAddress2(I2C3, 0, LL_I2C_OWNADDRESS2_NOMASK);
  LL_I2C_DisableOwnAddress2(I2C3);
  LL_I2C_DisableGeneralCall(I2C3);
  LL_I2C_EnableClockStretching(I2C3);

  /** I2C Fast mode Plus enable
  */
  LL_SYSCFG_EnableFastModePlus(LL_SYSCFG_I2C_FASTMODEPLUS_I2C3);

}

static void MX_TIM1_Init(void)
{

  LL_TIM_InitTypeDef TIM_InitStruct = {0};
  LL_TIM_OC_InitTypeDef TIM_OC_InitStruct = {0};
  LL_TIM_BDTR_InitTypeDef TIM_BDTRInitStruct = {0};

  LL_GPIO_InitTypeDef GPIO_InitStruct = {0};

  /* Peripheral clock enable */
  LL_APB2_GRP1_EnableClock(LL_APB2_GRP1_PERIPH_TIM1);

  /* TIM1 DMA Init */

  /* TIM1_CH4 Init */
  LL_DMA_SetPeriphRequest(DMA1, LL_DMA_CHANNEL_4, LL_DMAMUX_REQ_TIM1_CH4);

  LL_DMA_SetDataTransferDirection(DMA1, LL_DMA_CHANNEL_4, LL_DMA_DIRECTION_MEMORY_TO_PERIPH);

  LL_DMA_SetChannelPriorityLevel(DMA1, LL_DMA_CHANNEL_4, LL_DMA_PRIORITY_VERYHIGH);

  LL_DMA_SetMode(DMA1, LL_DMA_CHANNEL_4, LL_DMA_MODE_CIRCULAR);

  LL_DMA_SetPeriphIncMode(DMA1, LL_DMA_CHANNEL_4, LL_DMA_PERIPH_NOINCREMENT);

  LL_DMA_SetMemoryIncMode(DMA1, LL_DMA_CHANNEL_4, LL_DMA_MEMORY_INCREMENT);

  LL_DMA_SetPeriphSize(DMA1, LL_DMA_CHANNEL_4, LL_DMA_PDATAALIGN_HALFWORD);

  LL_DMA_SetMemorySize(DMA1, LL_DMA_CHANNEL_4, LL_DMA_MDATAALIGN_HALFWORD);

  /* TIM1 interrupt Init */
  NVIC_SetPriority(TIM1_UP_TIM16_IRQn, NVIC_EncodePriority(NVIC_GetPriorityGrouping(),1, 0));
  NVIC_EnableIRQ(TIM1_UP_TIM16_IRQn);

  TIM_InitStruct.Prescaler = 0;
  TIM_InitStruct.CounterMode = LL_TIM_COUNTERMODE_CENTER_UP_DOWN;
  TIM_InitStruct.Autoreload = ((PWM_PERIOD_CYCLES) / 2);
  TIM_InitStruct.ClockDivision = LL_TIM_CLOCKDIVISION_DIV1;
  TIM_InitStruct.RepetitionCounter = 0;
  LL_TIM_Init(TIM1, &TIM_InitStruct);
  LL_TIM_DisableARRPreload(TIM1);
  LL_TIM_SetClockSource(TIM1, LL_TIM_CLOCKSOURCE_INTERNAL);
  LL_TIM_OC_EnablePreload(TIM1, LL_TIM_CHANNEL_CH1);
  TIM_OC_InitStruct.OCMode = LL_TIM_OCMODE_PWM1;
  TIM_OC_InitStruct.OCState = LL_TIM_OCSTATE_DISABLE;
  TIM_OC_InitStruct.OCNState = LL_TIM_OCSTATE_DISABLE;
  TIM_OC_InitStruct.CompareValue = 300;
  TIM_OC_InitStruct.OCPolarity = LL_TIM_OCPOLARITY_HIGH;
  TIM_OC_InitStruct.OCNPolarity = LL_TIM_OCPOLARITY_HIGH;
  TIM_OC_InitStruct.OCIdleState = LL_TIM_OCIDLESTATE_LOW;
  TIM_OC_InitStruct.OCNIdleState = LL_TIM_OCIDLESTATE_LOW;
  LL_TIM_OC_Init(TIM1, LL_TIM_CHANNEL_CH1, &TIM_OC_InitStruct);
  LL_TIM_OC_DisableFast(TIM1, LL_TIM_CHANNEL_CH1);
  LL_TIM_OC_EnablePreload(TIM1, LL_TIM_CHANNEL_CH2);
  TIM_OC_InitStruct.CompareValue = 600;
  LL_TIM_OC_Init(TIM1, LL_TIM_CHANNEL_CH2, &TIM_OC_InitStruct);
  LL_TIM_OC_DisableFast(TIM1, LL_TIM_CHANNEL_CH2);
  LL_TIM_OC_EnablePreload(TIM1, LL_TIM_CHANNEL_CH3);
  TIM_OC_InitStruct.CompareValue = 900;
  LL_TIM_OC_Init(TIM1, LL_TIM_CHANNEL_CH3, &TIM_OC_InitStruct);
  LL_TIM_OC_DisableFast(TIM1, LL_TIM_CHANNEL_CH3);
  TIM_OC_InitStruct.OCMode = LL_TIM_OCMODE_TOGGLE;
  TIM_OC_InitStruct.CompareValue = 0;
  LL_TIM_OC_Init(TIM1, LL_TIM_CHANNEL_CH4, &TIM_OC_InitStruct);
  LL_TIM_OC_DisableFast(TIM1, LL_TIM_CHANNEL_CH4);
  LL_TIM_SetTriggerOutput(TIM1, LL_TIM_TRGO_RESET);
  LL_TIM_SetTriggerOutput2(TIM1, LL_TIM_TRGO2_OC4_RISINGFALLING);
  LL_TIM_DisableMasterSlaveMode(TIM1);
  TIM_BDTRInitStruct.OSSRState = LL_TIM_OSSR_DISABLE;
  TIM_BDTRInitStruct.OSSIState = LL_TIM_OSSI_DISABLE;
  TIM_BDTRInitStruct.LockLevel = LL_TIM_LOCKLEVEL_OFF;
  TIM_BDTRInitStruct.DeadTime = 0;
  TIM_BDTRInitStruct.BreakState = LL_TIM_BREAK_DISABLE;
  TIM_BDTRInitStruct.BreakPolarity = LL_TIM_BREAK_POLARITY_HIGH;
  TIM_BDTRInitStruct.BreakFilter = LL_TIM_BREAK_FILTER_FDIV1;
  TIM_BDTRInitStruct.BreakAFMode = LL_TIM_BREAK_AFMODE_INPUT;
  TIM_BDTRInitStruct.Break2State = LL_TIM_BREAK2_DISABLE;
  TIM_BDTRInitStruct.Break2Polarity = LL_TIM_BREAK2_POLARITY_HIGH;
  TIM_BDTRInitStruct.Break2Filter = LL_TIM_BREAK2_FILTER_FDIV1;
  TIM_BDTRInitStruct.Break2AFMode = LL_TIM_BREAK_AFMODE_INPUT;
  TIM_BDTRInitStruct.AutomaticOutput = LL_TIM_AUTOMATICOUTPUT_DISABLE;
  LL_TIM_BDTR_Init(TIM1, &TIM_BDTRInitStruct);
  LL_AHB2_GRP1_EnableClock(LL_AHB2_GRP1_PERIPH_GPIOE);
  /**TIM1 GPIO Configuration
  PE8   ------> TIM1_CH1N
  PE9   ------> TIM1_CH1
  PE10   ------> TIM1_CH2N
  PE11   ------> TIM1_CH2
  PE12   ------> TIM1_CH3N
  PE13   ------> TIM1_CH3
  */
  GPIO_InitStruct.Pin = M1_PWM_UL_Pin;
  GPIO_InitStruct.Mode = LL_GPIO_MODE_ALTERNATE;
  GPIO_InitStruct.Speed = LL_GPIO_SPEED_FREQ_HIGH;
  GPIO_InitStruct.OutputType = LL_GPIO_OUTPUT_PUSHPULL;
  GPIO_InitStruct.Pull = LL_GPIO_PULL_DOWN;
  GPIO_InitStruct.Alternate = LL_GPIO_AF_2;
  LL_GPIO_Init(M1_PWM_UL_GPIO_Port, &GPIO_InitStruct);

  GPIO_InitStruct.Pin = M1_PWM_UH_Pin;
  GPIO_InitStruct.Mode = LL_GPIO_MODE_ALTERNATE;
  GPIO_InitStruct.Speed = LL_GPIO_SPEED_FREQ_HIGH;
  GPIO_InitStruct.OutputType = LL_GPIO_OUTPUT_PUSHPULL;
  GPIO_InitStruct.Pull = LL_GPIO_PULL_DOWN;
  GPIO_InitStruct.Alternate = LL_GPIO_AF_2;
  LL_GPIO_Init(M1_PWM_UH_GPIO_Port, &GPIO_InitStruct);

  GPIO_InitStruct.Pin = M1_PWM_VL_Pin;
  GPIO_InitStruct.Mode = LL_GPIO_MODE_ALTERNATE;
  GPIO_InitStruct.Speed = LL_GPIO_SPEED_FREQ_HIGH;
  GPIO_InitStruct.OutputType = LL_GPIO_OUTPUT_PUSHPULL;
  GPIO_InitStruct.Pull = LL_GPIO_PULL_DOWN;
  GPIO_InitStruct.Alternate = LL_GPIO_AF_2;
  LL_GPIO_Init(M1_PWM_VL_GPIO_Port, &GPIO_InitStruct);

  GPIO_InitStruct.Pin = M1_PWM_VH_Pin;
  GPIO_InitStruct.Mode = LL_GPIO_MODE_ALTERNATE;
  GPIO_InitStruct.Speed = LL_GPIO_SPEED_FREQ_HIGH;
  GPIO_InitStruct.OutputType = LL_GPIO_OUTPUT_PUSHPULL;
  GPIO_InitStruct.Pull = LL_GPIO_PULL_DOWN;
  GPIO_InitStruct.Alternate = LL_GPIO_AF_2;
  LL_GPIO_Init(M1_PWM_VH_GPIO_Port, &GPIO_InitStruct);

  GPIO_InitStruct.Pin = M1_PWM_WL_Pin;
  GPIO_InitStruct.Mode = LL_GPIO_MODE_ALTERNATE;
  GPIO_InitStruct.Speed = LL_GPIO_SPEED_FREQ_HIGH;
  GPIO_InitStruct.OutputType = LL_GPIO_OUTPUT_PUSHPULL;
  GPIO_InitStruct.Pull = LL_GPIO_PULL_DOWN;
  GPIO_InitStruct.Alternate = LL_GPIO_AF_2;
  LL_GPIO_Init(M1_PWM_WL_GPIO_Port, &GPIO_InitStruct);

  GPIO_InitStruct.Pin = M1_PWM_WH_Pin;
  GPIO_InitStruct.Mode = LL_GPIO_MODE_ALTERNATE;
  GPIO_InitStruct.Speed = LL_GPIO_SPEED_FREQ_HIGH;
  GPIO_InitStruct.OutputType = LL_GPIO_OUTPUT_PUSHPULL;
  GPIO_InitStruct.Pull = LL_GPIO_PULL_DOWN;
  GPIO_InitStruct.Alternate = LL_GPIO_AF_2;
  LL_GPIO_Init(M1_PWM_WH_GPIO_Port, &GPIO_InitStruct);

}

static void MX_TIM8_Init(void)
{

  LL_TIM_InitTypeDef TIM_InitStruct = {0};
  LL_TIM_OC_InitTypeDef TIM_OC_InitStruct = {0};
  LL_TIM_BDTR_InitTypeDef TIM_BDTRInitStruct = {0};

  LL_GPIO_InitTypeDef GPIO_InitStruct = {0};

  /* Peripheral clock enable */
  LL_APB2_GRP1_EnableClock(LL_APB2_GRP1_PERIPH_TIM8);

  /* TIM8 interrupt Init */
  NVIC_SetPriority(TIM8_UP_IRQn, NVIC_EncodePriority(NVIC_GetPriorityGrouping(),0, 0));
  NVIC_EnableIRQ(TIM8_UP_IRQn);
  NVIC_SetPriority(TIM8_CC_IRQn, NVIC_EncodePriority(NVIC_GetPriorityGrouping(),0, 0));
  NVIC_EnableIRQ(TIM8_CC_IRQn);

  TIM_InitStruct.Prescaler = 0;
  TIM_InitStruct.CounterMode = LL_TIM_COUNTERMODE_UP;
  TIM_InitStruct.Autoreload = 8000;
  TIM_InitStruct.ClockDivision = LL_TIM_CLOCKDIVISION_DIV1;
  TIM_InitStruct.RepetitionCounter = 0;
  LL_TIM_Init(TIM8, &TIM_InitStruct);
  LL_TIM_DisableARRPreload(TIM8);
  LL_TIM_SetClockSource(TIM8, LL_TIM_CLOCKSOURCE_INTERNAL);
  LL_TIM_OC_EnablePreload(TIM8, LL_TIM_CHANNEL_CH1);
  TIM_OC_InitStruct.OCMode = LL_TIM_OCMODE_PWM1;
  TIM_OC_InitStruct.OCState = LL_TIM_OCSTATE_DISABLE;
  TIM_OC_InitStruct.OCNState = LL_TIM_OCSTATE_DISABLE;
  TIM_OC_InitStruct.CompareValue = 4000;
  TIM_OC_InitStruct.OCPolarity = LL_TIM_OCPOLARITY_HIGH;
  TIM_OC_InitStruct.OCNPolarity = LL_TIM_OCPOLARITY_HIGH;
  TIM_OC_InitStruct.OCIdleState = LL_TIM_OCIDLESTATE_LOW;
  TIM_OC_InitStruct.OCNIdleState = LL_TIM_OCIDLESTATE_LOW;
  LL_TIM_OC_Init(TIM8, LL_TIM_CHANNEL_CH1, &TIM_OC_InitStruct);
  LL_TIM_OC_DisableFast(TIM8, LL_TIM_CHANNEL_CH1);
  LL_TIM_OC_EnablePreload(TIM8, LL_TIM_CHANNEL_CH4);
  TIM_OC_InitStruct.OCMode = LL_TIM_OCMODE_PWM2;
  TIM_OC_InitStruct.CompareValue = 2000;
  LL_TIM_OC_Init(TIM8, LL_TIM_CHANNEL_CH4, &TIM_OC_InitStruct);
  LL_TIM_OC_DisableFast(TIM8, LL_TIM_CHANNEL_CH4);
  LL_TIM_SetTriggerOutput(TIM8, LL_TIM_TRGO_RESET);
  LL_TIM_SetTriggerOutput2(TIM8, LL_TIM_TRGO2_OC4);
  LL_TIM_DisableMasterSlaveMode(TIM8);
  TIM_BDTRInitStruct.OSSRState = LL_TIM_OSSR_DISABLE;
  TIM_BDTRInitStruct.OSSIState = LL_TIM_OSSI_DISABLE;
  TIM_BDTRInitStruct.LockLevel = LL_TIM_LOCKLEVEL_OFF;
  TIM_BDTRInitStruct.DeadTime = 0;
  TIM_BDTRInitStruct.BreakState = LL_TIM_BREAK_DISABLE;
  TIM_BDTRInitStruct.BreakPolarity = LL_TIM_BREAK_POLARITY_HIGH;
  TIM_BDTRInitStruct.BreakFilter = LL_TIM_BREAK_FILTER_FDIV1;
  TIM_BDTRInitStruct.BreakAFMode = LL_TIM_BREAK_AFMODE_INPUT;
  TIM_BDTRInitStruct.Break2State = LL_TIM_BREAK2_DISABLE;
  TIM_BDTRInitStruct.Break2Polarity = LL_TIM_BREAK2_POLARITY_HIGH;
  TIM_BDTRInitStruct.Break2Filter = LL_TIM_BREAK2_FILTER_FDIV1;
  TIM_BDTRInitStruct.Break2AFMode = LL_TIM_BREAK_AFMODE_INPUT;
  TIM_BDTRInitStruct.AutomaticOutput = LL_TIM_AUTOMATICOUTPUT_DISABLE;
  LL_TIM_BDTR_Init(TIM8, &TIM_BDTRInitStruct);
  LL_AHB2_GRP1_EnableClock(LL_AHB2_GRP1_PERIPH_GPIOA);
  /**TIM8 GPIO Configuration
  PA15   ------> TIM8_CH1
  */
  GPIO_InitStruct.Pin = LL_GPIO_PIN_15;
  GPIO_InitStruct.Mode = LL_GPIO_MODE_ALTERNATE;
  GPIO_InitStruct.Speed = LL_GPIO_SPEED_FREQ_LOW;
  GPIO_InitStruct.OutputType = LL_GPIO_OUTPUT_PUSHPULL;
  GPIO_InitStruct.Pull = LL_GPIO_PULL_NO;
  GPIO_InitStruct.Alternate = LL_GPIO_AF_2;
  LL_GPIO_Init(GPIOA, &GPIO_InitStruct);

}

static void MX_USART2_UART_Init(void)
{

  LL_USART_InitTypeDef USART_InitStruct = {0};

  LL_GPIO_InitTypeDef GPIO_InitStruct = {0};

  LL_RCC_SetUSARTClockSource(LL_RCC_USART2_CLKSOURCE_HSI);

  /* Peripheral clock enable */
  LL_APB1_GRP1_EnableClock(LL_APB1_GRP1_PERIPH_USART2);

  LL_AHB2_GRP1_EnableClock(LL_AHB2_GRP1_PERIPH_GPIOB);
  /**USART2 GPIO Configuration
  PB3   ------> USART2_TX
  PB4   ------> USART2_RX
  */
  GPIO_InitStruct.Pin = UART2_DBG_TX_Pin;
  GPIO_InitStruct.Mode = LL_GPIO_MODE_ALTERNATE;
  GPIO_InitStruct.Speed = LL_GPIO_SPEED_FREQ_LOW;
  GPIO_InitStruct.OutputType = LL_GPIO_OUTPUT_PUSHPULL;
  GPIO_InitStruct.Pull = LL_GPIO_PULL_NO;
  GPIO_InitStruct.Alternate = LL_GPIO_AF_7;
  LL_GPIO_Init(UART2_DBG_TX_GPIO_Port, &GPIO_InitStruct);

  GPIO_InitStruct.Pin = UART2_DBG_RX_Pin;
  GPIO_InitStruct.Mode = LL_GPIO_MODE_ALTERNATE;
  GPIO_InitStruct.Speed = LL_GPIO_SPEED_FREQ_LOW;
  GPIO_InitStruct.OutputType = LL_GPIO_OUTPUT_PUSHPULL;
  GPIO_InitStruct.Pull = LL_GPIO_PULL_NO;
  GPIO_InitStruct.Alternate = LL_GPIO_AF_7;
  LL_GPIO_Init(UART2_DBG_RX_GPIO_Port, &GPIO_InitStruct);

  /* USART2 interrupt Init */
  NVIC_SetPriority(USART2_IRQn, NVIC_EncodePriority(NVIC_GetPriorityGrouping(),7, 0));
  NVIC_EnableIRQ(USART2_IRQn);

  USART_InitStruct.PrescalerValue = LL_USART_PRESCALER_DIV1;
  USART_InitStruct.BaudRate = 921600;
  USART_InitStruct.DataWidth = LL_USART_DATAWIDTH_8B;
  USART_InitStruct.StopBits = LL_USART_STOPBITS_1;
  USART_InitStruct.Parity = LL_USART_PARITY_NONE;
  USART_InitStruct.TransferDirection = LL_USART_DIRECTION_TX_RX;
  USART_InitStruct.HardwareFlowControl = LL_USART_HWCONTROL_NONE;
  USART_InitStruct.OverSampling = LL_USART_OVERSAMPLING_16;
  LL_USART_Init(USART2, &USART_InitStruct);
  LL_USART_SetTXFIFOThreshold(USART2, LL_USART_FIFOTHRESHOLD_1_8);
  LL_USART_SetRXFIFOThreshold(USART2, LL_USART_FIFOTHRESHOLD_1_8);
  LL_USART_DisableFIFO(USART2);
  LL_USART_ConfigAsyncMode(USART2);

  LL_USART_Enable(USART2);

  /* Polling USART2 initialisation */
  while((!(LL_USART_IsActiveFlag_TEACK(USART2))) || (!(LL_USART_IsActiveFlag_REACK(USART2))))
  {
  }

}

static void MX_DMA_Init(void)
{

  /* Init with LL driver */
  /* DMA controller clock enable */
  LL_AHB1_GRP1_EnableClock(LL_AHB1_GRP1_PERIPH_DMAMUX1);
  LL_AHB1_GRP1_EnableClock(LL_AHB1_GRP1_PERIPH_DMA1);

  /* DMA interrupt init */
  /* DMA1_Channel1_IRQn interrupt configuration */
  NVIC_SetPriority(DMA1_Channel1_IRQn, NVIC_EncodePriority(NVIC_GetPriorityGrouping(),0, 0));
  NVIC_EnableIRQ(DMA1_Channel1_IRQn);
  /* DMA1_Channel2_IRQn interrupt configuration */
  NVIC_SetPriority(DMA1_Channel2_IRQn, NVIC_EncodePriority(NVIC_GetPriorityGrouping(),0, 0));
  NVIC_EnableIRQ(DMA1_Channel2_IRQn);
  /* DMA1_Channel4_IRQn interrupt configuration */
  NVIC_SetPriority(DMA1_Channel4_IRQn, NVIC_EncodePriority(NVIC_GetPriorityGrouping(),0, 0));
  NVIC_EnableIRQ(DMA1_Channel4_IRQn);

}

static void MX_GPIO_Init(void)
{
  LL_EXTI_InitTypeDef EXTI_InitStruct = {0};
  LL_GPIO_InitTypeDef GPIO_InitStruct = {0};

  /* GPIO Ports Clock Enable */
  LL_AHB2_GRP1_EnableClock(LL_AHB2_GRP1_PERIPH_GPIOC);
  LL_AHB2_GRP1_EnableClock(LL_AHB2_GRP1_PERIPH_GPIOF);
  LL_AHB2_GRP1_EnableClock(LL_AHB2_GRP1_PERIPH_GPIOE);
  LL_AHB2_GRP1_EnableClock(LL_AHB2_GRP1_PERIPH_GPIOB);
  LL_AHB2_GRP1_EnableClock(LL_AHB2_GRP1_PERIPH_GPIOA);

  /**/
  LL_GPIO_ResetOutputPin(DBG_ALARM_LED_GPIO_Port, DBG_ALARM_LED_Pin);

  /**/
  LL_GPIO_ResetOutputPin(GPIOA, LL_GPIO_PIN_8);

  /**/
  LL_GPIO_ResetOutputPin(GPIOA, LL_GPIO_PIN_11);

  /**/
  LL_GPIO_ResetOutputPin(GPIOA, LL_GPIO_PIN_12);

  /**/
  LL_GPIO_SetOutputPin(GD_WAKE_GPIO_Port, GD_WAKE_Pin);

  /**/
  GPIO_InitStruct.Pin = DBG_ALARM_LED_Pin;
  GPIO_InitStruct.Mode = LL_GPIO_MODE_OUTPUT;
  GPIO_InitStruct.Speed = LL_GPIO_SPEED_FREQ_LOW;
  GPIO_InitStruct.OutputType = LL_GPIO_OUTPUT_PUSHPULL;
  GPIO_InitStruct.Pull = LL_GPIO_PULL_NO;
  LL_GPIO_Init(DBG_ALARM_LED_GPIO_Port, &GPIO_InitStruct);

  /**/
  GPIO_InitStruct.Pin = GD_WAKE_Pin;
  GPIO_InitStruct.Mode = LL_GPIO_MODE_OUTPUT;
  GPIO_InitStruct.Speed = LL_GPIO_SPEED_FREQ_LOW;
  GPIO_InitStruct.OutputType = LL_GPIO_OUTPUT_PUSHPULL;
  GPIO_InitStruct.Pull = LL_GPIO_PULL_NO;
  LL_GPIO_Init(GD_WAKE_GPIO_Port, &GPIO_InitStruct);

  /**/
  GPIO_InitStruct.Pin = LL_GPIO_PIN_8;
  GPIO_InitStruct.Mode = LL_GPIO_MODE_OUTPUT;
  GPIO_InitStruct.Speed = LL_GPIO_SPEED_FREQ_LOW;
  GPIO_InitStruct.OutputType = LL_GPIO_OUTPUT_PUSHPULL;
  GPIO_InitStruct.Pull = LL_GPIO_PULL_NO;
  LL_GPIO_Init(GPIOA, &GPIO_InitStruct);

  /**/
  GPIO_InitStruct.Pin = LL_GPIO_PIN_11;
  GPIO_InitStruct.Mode = LL_GPIO_MODE_OUTPUT;
  GPIO_InitStruct.Speed = LL_GPIO_SPEED_FREQ_LOW;
  GPIO_InitStruct.OutputType = LL_GPIO_OUTPUT_PUSHPULL;
  GPIO_InitStruct.Pull = LL_GPIO_PULL_NO;
  LL_GPIO_Init(GPIOA, &GPIO_InitStruct);

  /**/
  GPIO_InitStruct.Pin = LL_GPIO_PIN_12;
  GPIO_InitStruct.Mode = LL_GPIO_MODE_OUTPUT;
  GPIO_InitStruct.Speed = LL_GPIO_SPEED_FREQ_LOW;
  GPIO_InitStruct.OutputType = LL_GPIO_OUTPUT_PUSHPULL;
  GPIO_InitStruct.Pull = LL_GPIO_PULL_NO;
  LL_GPIO_Init(GPIOA, &GPIO_InitStruct);

  /**/
  LL_SYSCFG_SetEXTISource(LL_SYSCFG_EXTI_PORTE, LL_SYSCFG_EXTI_LINE14);

  /**/
  LL_SYSCFG_SetEXTISource(LL_SYSCFG_EXTI_PORTE, LL_SYSCFG_EXTI_LINE15);

  /**/
  LL_SYSCFG_SetEXTISource(LL_SYSCFG_EXTI_PORTB, LL_SYSCFG_EXTI_LINE10);

  /**/
  EXTI_InitStruct.Line_0_31 = LL_EXTI_LINE_14;
  EXTI_InitStruct.LineCommand = ENABLE;
  EXTI_InitStruct.Mode = LL_EXTI_MODE_IT;
  EXTI_InitStruct.Trigger = LL_EXTI_TRIGGER_RISING_FALLING;
  LL_EXTI_Init(&EXTI_InitStruct);

  /**/
  EXTI_InitStruct.Line_0_31 = LL_EXTI_LINE_15;
  EXTI_InitStruct.LineCommand = ENABLE;
  EXTI_InitStruct.Mode = LL_EXTI_MODE_IT;
  EXTI_InitStruct.Trigger = LL_EXTI_TRIGGER_FALLING;
  LL_EXTI_Init(&EXTI_InitStruct);

  /**/
  EXTI_InitStruct.Line_0_31 = LL_EXTI_LINE_10;
  EXTI_InitStruct.LineCommand = ENABLE;
  EXTI_InitStruct.Mode = LL_EXTI_MODE_IT;
  EXTI_InitStruct.Trigger = LL_EXTI_TRIGGER_RISING;
  LL_EXTI_Init(&EXTI_InitStruct);

  /**/
  LL_GPIO_SetPinPull(GPIOE, LL_GPIO_PIN_14, LL_GPIO_PULL_UP);

  /**/
  LL_GPIO_SetPinPull(GPIOE, LL_GPIO_PIN_15, LL_GPIO_PULL_UP);

  /**/
  LL_GPIO_SetPinPull(Start_Stop_GPIO_Port, Start_Stop_Pin, LL_GPIO_PULL_NO);

  /**/
  LL_GPIO_SetPinMode(GPIOE, LL_GPIO_PIN_14, LL_GPIO_MODE_INPUT);

  /**/
  LL_GPIO_SetPinMode(GPIOE, LL_GPIO_PIN_15, LL_GPIO_MODE_INPUT);

  /**/
  LL_GPIO_SetPinMode(Start_Stop_GPIO_Port, Start_Stop_Pin, LL_GPIO_MODE_INPUT);

  /* EXTI interrupt init*/
  NVIC_SetPriority(EXTI15_10_IRQn, NVIC_EncodePriority(NVIC_GetPriorityGrouping(),6, 0));
  NVIC_EnableIRQ(EXTI15_10_IRQn);

}

/* USER CODE BEGIN 4 */
void WDG_Enable(void)
{
#define WATCHDOG_ENABLE
#ifdef WATCHDOG_ENABLE
	sIWDG.Enable = ENABLE;
	if(sIWDG.Enable == ENABLE)
	{
  	/* ****************************** WWDG Init *******************************
		 The independent watchdog (IWDG) is clocked by its own dedicated low-speed
    clock (LSI) and thus stays active even if the main clock fails.

		 Independent watchdog basic

Configuring the IWDG when the window option is disabled
When the window option it is not used, the IWDG can be configured as follows:
1. Enable the IWDG by writing 0x0000 CCCC in the IWDG key register (IWDG_KR).
2. Enable register access by writing 0x0000 5555 in the IWDG key register (IWDG_KR).
3. Write the prescaler by programming the IWDG prescaler register (IWDG_PR) from 0 to 7.
4. Write the IWDG reload register (IWDG_RLR).
5. Wait for the registers to be updated (IWDG_SR = 0x0000 0000).
6. Refresh the counter value with IWDG_RLR (IWDG_KR = 0x0000 AAAA).

			** Independent watchdog timeout
				- tIWDG = tLSI(32kHz) x 2^(2+PR[2:0]) × (IWDG_RLR[11:0]+1) (ms)
		 		* when PR[2:0]=0 and IWDG_RLR[11:0] = 0xFFF(4095)
		 		  timeout = (1/32) x 2^(2+0) x (4095) = 256.88msec
		 		* when PR[2:0]=1 and IWDG_RLR[11:0] = 0xFFF(4095)
		 		  timeout = (1/32) x 2^(2+1) x (4095) = 1023.75msec

IWDG_PR - Bits 2:0 PR[2:0]: Prescaler divider
These bits are write access protected see Section 42.3.5: Register access protection. They are
written by software to select the prescaler divider feeding the counter clock. PVU bit of the
IWDG status register (IWDG_SR) must be reset in order to be able to change the prescaler
divider.
000: divider /4
001: divider /8
010: divider /16
011: divider /32
100: divider /64
101: divider /128
110: divider /256
111: divider /256

  	************************************************************************* */

		User_printf(SCI_DEBUG, "\r\n Enable Independent Watchdog before entering main loop,.... ");
		sIWDG.Reload = 0xFFF;
		sIWDG.Window = 0xFFF;
		sIWDG.Prescaler = LL_IWDG_PRESCALER_8;
		sIWDG.Timeout_msec = (1<<(2+sIWDG.Prescaler)) * (sIWDG.Reload & 0xFFF) / (LSI_VALUE/1000); // msec

		LL_IWDG_EnableWriteAccess(IWDG); //WRITE_REG(IWDG->KR, LL_IWDG_KEY_WR_ACCESS_ENABLE);
		LL_IWDG_SetPrescaler(IWDG, sIWDG.Prescaler); //WRITE_REG(IWDG->PR, IWDG_PR_PR & sIWDG.Prescaler);
		LL_IWDG_SetReloadCounter(IWDG, sIWDG.Reload); //WRITE_REG(IWDG->RLR, IWDG_RLR_RL & sIWDG.Reload );
		LL_IWDG_Enable(IWDG); //WRITE_REG(IWDG->KR, LL_IWDG_KEY_ENABLE);
		while (!LL_IWDG_IsReady(IWDG)); //while (((READ_BIT(IWDG->SR, IWDG_SR_PVU | IWDG_SR_RVU | IWDG_SR_WVU) == 0U) ? 1UL : 0UL) != 1); //
		LL_IWDG_ReloadCounter(IWDG); // WRITE_REG(IWDG->KR, LL_IWDG_KEY_RELOAD);
	}

	sWWDG.Enable = DISABLE;
	if(sWWDG.Enable == ENABLE)
	{
  	/* ****************************** WWDG Init *******************************
		 The system window watchdog (WWDG) is used to detect the occurrence of a
		software fault, usually generated by external interference or by unforeseen
		logical conditions, which causes the application program to abandon its
		normal sequence.

		 Window watchdog basic
		  1. Down Timer counter value: T[6:0]
		 		- T[6:0] : T6 bit(0x40) must be set. If not immediate reset.
		 		- T[5:0] : it contain the number of increments that
									represent the time delay before the watchdog produces a reset.
									(max 0x3F)
				- A reset is produced when T6 becomes cleared
					(T[6:0] is decremented from 0x40 to 0x3F)

			2. window register value : W[6:0]
		 		- Refresh not allowed when T[6:0] >= W[6:0]
				- Refresh allowed when T[6:0] < W[6:0]

			3. Window watchdog timeout
				- tWWDG = tPCLK × 4096 × 2^WDGTB[2:0] × (T[5:0] + 1) (ms)
		 		* when tPCLK = 48Mhz, WDGTB[2:0] = 3 and T[5:0] = 0x3F
		 		  timeout = (1/48000) x 4096 x 2^3 x (63+1) = 43.69msec
		 		* when tPCLK = 170Mhz, WDGTB[2:0] = 5 and T[5:0] = 0x3F
		 		  timeout = (1/170000) x 4096 x 2^5 x (63+1) = 49.34msec
		 		* when tPCLK = 170Mhz, WDGTB[2:0] = 7 and T[5:0] = 0x3F
		 		  timeout = (1/170000) x 4096 x 2^7 x (63+1) = 197.38msec

					WWDG_CFR - Bits 13:11 WDGTB[2:0]: Timer base
					The timebase of the prescaler can be modified as follows:
					000: CK Counter Clock (PCLK div 4096) div 1
					001: CK Counter Clock (PCLK div 4096) div 2
					010: CK Counter Clock (PCLK div 4096) div 4
					011: CK Counter Clock (PCLK div 4096) div 8
					100: CK Counter Clock (PCLK div 4096) div 16
					101: CK Counter Clock (PCLK div 4096) div 32
					110: CK Counter Clock (PCLK div 4096) div 64
					111: CK Counter Clock (PCLK div 4096) div 128

  	************************************************************************* */
		User_printf(SCI_DEBUG, "\r\n Enable Independent Watchdog before entering main loop,.... ");
		sWWDG.Reload = 0x7F; // 0x7F = 0x40 | 0x3F(63)
		sWWDG.Window = 0x7F; // 0x7F = 0x40 | 0x3F(63)
		sWWDG.Prescaler = (LL_WWDG_PRESCALER_128 >> WWDG_CFR_WDGTB_Pos);
		sWWDG.Timeout_msec = 4096 * (1<<sWWDG.Prescaler) * ((sWWDG.Reload & 0x3F)+1) /(REF_TIM_CLK_MHz) / 1000;  // msec

		LL_WWDG_SetCounter(WWDG, sWWDG.Reload); // MODIFY_REG(WWDGx->CR, WWDG_CR_T, Counter);
		LL_WWDG_SetWindow(WWDG, sWWDG.Window); // MODIFY_REG(WWDGx->CFR, WWDG_CFR_W, Window);
		LL_WWDG_SetPrescaler(WWDG, sWWDG.Prescaler); // MODIFY_REG(WWDGx->CFR, WWDG_CFR_WDGTB, Prescaler);
		LL_WWDG_Enable(WWDG); // SET_BIT(WWDG->CR, WWDG_CR_WDGA);
	}
#endif
}

void STSPIN32G4_STBY_Recovery_for_CLK(void)
{
	LL_IWDG_ReloadCounter(IWDG);
	User_printf(SCI_DEBUG, "\r\n //*********************************************************//");
	User_printf(SCI_DEBUG, "\r\n //********    SYSTEM RECOVERY FROM STANDBY MODE    ********//");

  /* Configure the system clock */
	LL_IWDG_ReloadCounter(IWDG);
	User_printf(SCI_DEBUG, "\r\n //********    Configure the system clock ... ");
  SystemClock_Config();

	LL_IWDG_ReloadCounter(IWDG);
	User_printf(SCI_DEBUG, "\r\n //********    Systick interrupt enable ... ");
  SysTick->CTRL |= SysTick_CTRL_TICKINT_Msk;

	LL_IWDG_ReloadCounter(IWDG);
	User_printf(SCI_DEBUG, "\r\n //********    Initialize all configured peripherals... ");
  /* Initialize all configured peripherals */
	LL_IWDG_ReloadCounter(IWDG);
  MX_GPIO_Init();
  MX_DMA_Init();
  MX_ADC1_Init();
  MX_CORDIC_Init();
  MX_I2C3_Init();
  MX_TIM1_Init();
  MX_USART2_UART_Init();
  MX_ADC2_Init();
  MX_TIM8_Init();
  /* USER CODE BEGIN 2 */

	/** USER_CODE_06: User Peripheral initializations**/
	LL_IWDG_ReloadCounter(IWDG);
	User_printf(SCI_DEBUG, "\r\n //********    System recovered from standby mode   ********//");
	User_printf(SCI_DEBUG, "\r\n //*********************************************************//");
	MACHINE_NAME(SCI_DEBUG);
}

/* USER CODE END 4 */

void Error_Handler(void)
{
  __disable_irq();
  while (1)
  {
  }
}
